# ATtiny44A device description
Architecture: AVR8; Family: tinyAVR
Registers are 8-bit, access not given, no defined reset value unless marked. A register's access mark holds for its fields unless they carry their own. Offsets are from the block's base; [hi:lo] are bit positions; {n}, {i} and the like mark numbered series.

## EEPROM
Instances: EEPROM 0x00
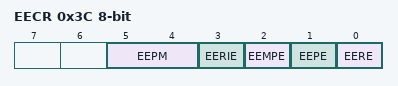
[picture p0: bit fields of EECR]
0x3C EECR — EEPROM Control Register
  [5:4] EEPM — EEPROM Programming Mode Bits
    0=ERASE_AND_WRITE_IN_ONE_OPERATION; 1=ERASE_ONLY; 2=WRITE_ONLY
  [3] EERIE — EEPROM Ready Interrupt Enable
  [2] EEMPE — EEPROM Master Write Enable
  [1] EEPE — EEPROM Write Enable
  [0] EERE — EEPROM Read Enable
0x3D EEDR — EEPROM Data Register
0x3E EEAR 16-bit bits used 8:0 — EEPROM Address Register Bytes

## WDT — Watchdog Timer
Instances: WDT 0x00
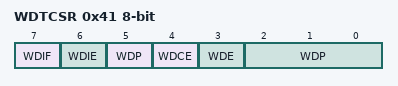
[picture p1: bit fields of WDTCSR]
0x41 WDTCSR — Watchdog Timer Control Register
  [7] WDIF — Watchdog Timeout Interrupt Flag
  [6] WDIE — Watchdog Timeout Interrupt Enable
  [4] WDCE — Watchdog Change Enable
  [3] WDE — Watch Dog Enable
  [5,2:0] WDP — Watchdog Timer Prescaler Bits
    0=OSCILLATOR_CYCLES_2K; 1=OSCILLATOR_CYCLES_4K; 2=OSCILLATOR_CYCLES_8K; 3=OSCILLATOR_CYCLES_16K; 4=OSCILLATOR_CYCLES_32K; 5=OSCILLATOR_CYCLES_64K; 6=OSCILLATOR_CYCLES_128K; 7=OSCILLATOR_CYCLES_256K; 8=OSCILLATOR_CYCLES_512K; 9=OSCILLATOR_CYCLES_1024K

## TC0 (TC8 module) — Timer/Counter, 8-bit
Instances: TC0 0x00
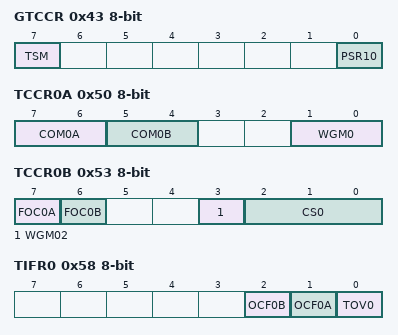
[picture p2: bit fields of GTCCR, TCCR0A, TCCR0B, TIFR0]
0x43 GTCCR — General Timer/Counter Control Register
  [7] TSM — Timer/Counter Synchronization Mode
  [0] PSR10 — Prescaler Reset Timer/CounterN
0x50 TCCR0A — Timer/Counter Control Register A
  [7:6] COM0A — Compare Match Output A Mode bits
  [5:4] COM0B — Compare Match Output B Mode bits
  [1:0] WGM0 — Waveform Generation Mode bits
0x52 TCNT0 — Timer/Counter0
0x53 TCCR0B — Timer/Counter Control Register B
  [7] FOC0A — Force Output Compare A
  [6] FOC0B — Force Output Compare B
  [3] WGM02 — Waveform Generation Mode bit 2
  [2:0] CS0 — Clock Select bits
    0=NO_CLOCK_SOURCE_STOPPED; 1=RUNNING_NO_PRESCALING; 2=RUNNING_CLK_8; 3=RUNNING_CLK_64; 4=RUNNING_CLK_256; 5=RUNNING_CLK_1024; 6=RUNNING_EXTCLK_TN_FALLING_EDGE; 7=RUNNING_EXTCLK_TN_RISING_EDGE
0x56 OCR0A — Timer/Counter0 Output Compare Register A
0x58 TIFR0 — Timer/Counter0 Interrupt Flag Register
  [2] OCF0B — Timer/Counter0 Output Compare Flag B
  [1] OCF0A — Timer/Counter0 Output Compare Flag A
  [0] TOV0 — Timer/Counter0 Overflow Flag
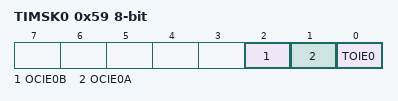
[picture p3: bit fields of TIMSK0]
0x59 TIMSK0 — Timer/Counter Interrupt Mask Register
  [2] OCIE0B — Timer/Counter0 Output Compare Match B Interrupt Enable
  [1] OCIE0A — Timer/Counter0 Output Compare Match A Interrupt Enable
  [0] TOIE0 — Timer/Counter0 Overflow Interrupt Enable
0x5C OCR0B — Timer/Counter0 Output Compare Register B

## TC1 (TC16 module) — Timer/Counter, 16-bit
Instances: TC1 0x00
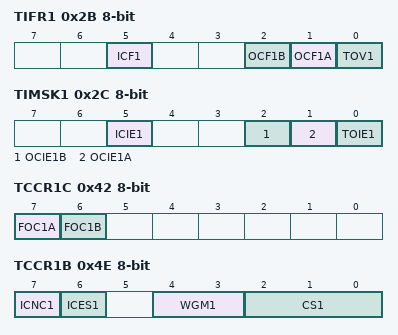
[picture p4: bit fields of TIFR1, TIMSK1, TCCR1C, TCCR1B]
0x2B TIFR1 — Timer/Counter Interrupt Flag register
  [5] ICF1 — Timer/Counter1 Input Capture Flag
  [2] OCF1B — Timer/Counter1 Output Compare B Match Flag
  [1] OCF1A — Timer/Counter1 Output Compare A Match Flag
  [0] TOV1 — Timer/Counter1 Overflow Flag
0x2C TIMSK1 — Timer/Counter1 Interrupt Mask Register
  [5] ICIE1 — Timer/Counter1 Input Capture Interrupt Enable
  [2] OCIE1B — Timer/Counter1 Output Compare B Match Interrupt Enable
  [1] OCIE1A — Timer/Counter1 Output Compare A Match Interrupt Enable
  [0] TOIE1 — Timer/Counter1 Overflow Interrupt Enable
0x42 TCCR1C — Timer/Counter1 Control Register C
  [7] FOC1A — Force Output Compare for Channel A
  [6] FOC1B — Force Output Compare for Channel B
0x44 ICR1 16-bit — Timer/Counter1 Input Capture Register Bytes
0x48 OCR1B 16-bit — Timer/Counter1 Output Compare Register B Bytes
0x4A OCR1A 16-bit — Timer/Counter1 Output Compare Register A Bytes
0x4C TCNT1 16-bit — Timer/Counter1 Bytes
0x4E TCCR1B — Timer/Counter1 Control Register B
  [7] ICNC1 — Input Capture 1 Noise Canceler
  [6] ICES1 — Input Capture 1 Edge Select
  [4:3] WGM1 (bit 2 of the value upward) — Waveform Generation Mode Bits
  [2:0] CS1 — Clock Select1 bits
    0=NO_CLOCK_SOURCE_STOPPED; 1=RUNNING_NO_PRESCALING; 2=RUNNING_CLK_8; 3=RUNNING_CLK_64; 4=RUNNING_CLK_256; 5=RUNNING_CLK_1024; 6=RUNNING_EXTCLK_TN_FALLING_EDGE; 7=RUNNING_EXTCLK_TN_RISING_EDGE
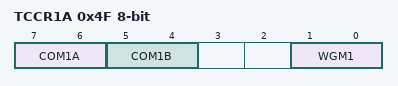
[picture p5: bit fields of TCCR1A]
0x4F TCCR1A — Timer/Counter1 Control Register A
  [7:6] COM1A — Compare Output Mode 1A, bits
  [5:4] COM1B — Compare Output Mode 1B, bits
  [1:0] WGM1 — Pulse Width Modulator Select Bits

## BOOT_LOAD — Bootloader
Instances: BOOT_LOAD 0x00
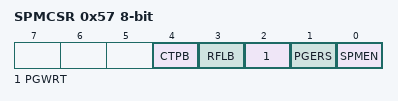
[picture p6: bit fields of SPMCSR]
0x57 SPMCSR — Store Program Memory Control Register
  [4] CTPB — Clear temporary page buffer
  [3] RFLB — Read fuse and lock bits
  [2] PGWRT — Page Write
  [1] PGERS — Page Erase
  [0] SPMEN — Store Program Memory Enable

## CPU — CPU Registers
Instances: CPU 0x00
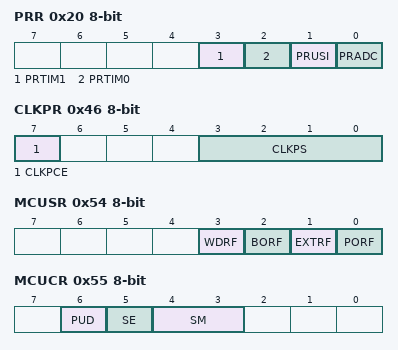
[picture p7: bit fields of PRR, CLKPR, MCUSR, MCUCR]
0x20 PRR — Power Reduction Register
  [3] PRTIM1 — Power Reduction Timer/Counter1
  [2] PRTIM0 — Power Reduction Timer/Counter0
  [1] PRUSI — Power Reduction USI
  [0] PRADC — Power Reduction ADC
{0x33+i} GPIOR{i} (i=0..2) — General Purpose I/O Register {i}
0x46 CLKPR — Clock Prescale Register
  [7] CLKPCE — Clock Prescaler Change Enable
  [3:0] CLKPS — Clock Prescaler Select Bits
    0=1; 1=2; 2=4; 3=8; 4=16; 5=32; 6=64; 7=128; 8=256
0x51 OSCCAL — Oscillator Calibration Value
  [7:0] OSCCAL — Oscillator Calibration
0x54 MCUSR — MCU Status Register
  [3] WDRF — Watchdog Reset Flag
  [2] BORF — Brown-out Reset Flag
  [1] EXTRF — External Reset Flag
  [0] PORF — Power-on reset flag
0x55 MCUCR — MCU Control Register
  [6] PUD — Pull-up Disable
  [5] SE — Sleep Enable
  [4:3] SM — Sleep Mode Select Bits
    0=IDLE; 1=ADC (ADC Noise Reduction (If Available)); 2=PDOWN (Power Down); 3=STDBY (Standby)
0x5D SP 16-bit bits used 8:0 — Stack Pointer
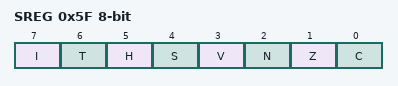
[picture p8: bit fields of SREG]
0x5F SREG — Status Register
  [7] I — Global Interrupt Enable
  [6] T — Bit Copy Storage
  [5] H — Half Carry Flag
  [4] S — Sign Bit
  [3] V — Two's Complement Overflow Flag
  [2] N — Negative Flag
  [1] Z — Zero Flag
  [0] C — Carry Flag
Value list OSCCAL_VALUE_ADDRESSES: 0=8_0_MHz
